# RX64M_PDC_Pilot register map
File version: 1.0
RX64M_PDC_Pilot peripheral registers generated from iodefine.h (pilot).
Registers are 32-bit, read-write, reset 0x0 unless marked. A register's access mark holds for its fields unless they carry their own. Offsets are from the block's base; lines under a group give offsets from that group; [hi:lo] are bit positions; {n}, {i} and the like mark numbered series; 'fields as' and 'values as' point back to an identical list; <NAME> marks a mode.

## Memory map
0x000A0500 PDC size 0x1C

## PDC
Base 0x000A0500
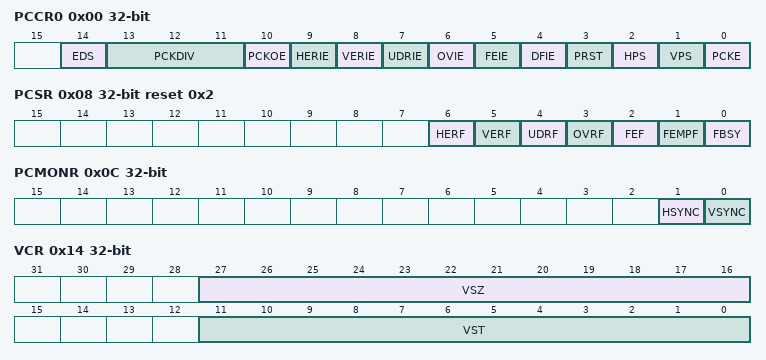
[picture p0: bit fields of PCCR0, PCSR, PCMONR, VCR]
0x00 PCCR0
  [14] EDS, [13:11] PCKDIV, [10] PCKOE, [9] HERIE, [8] VERIE, [7] UDRIE, [6] OVIE, [5] FEIE, [4] DFIE, [3] PRST, [2] HPS, [1] VPS, [0] PCKE
0x04 PCCR1
  [0] PCE
0x08 PCSR reset 0x2
  [6] HERF, [5] VERF, [4] UDRF, [3] OVRF, [2] FEF, [1] FEMPF, [0] FBSY
0x0C PCMONR ro
  [1] HSYNC, [0] VSYNC
0x10 PCDR ro
0x14 VCR
  [27:16] VSZ, [11:0] VST
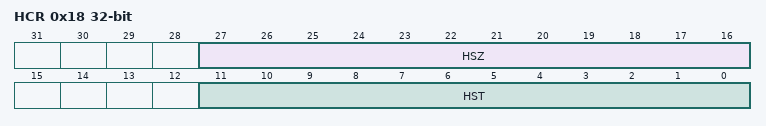
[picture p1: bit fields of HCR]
0x18 HCR
  [27:16] HSZ, [11:0] HST
